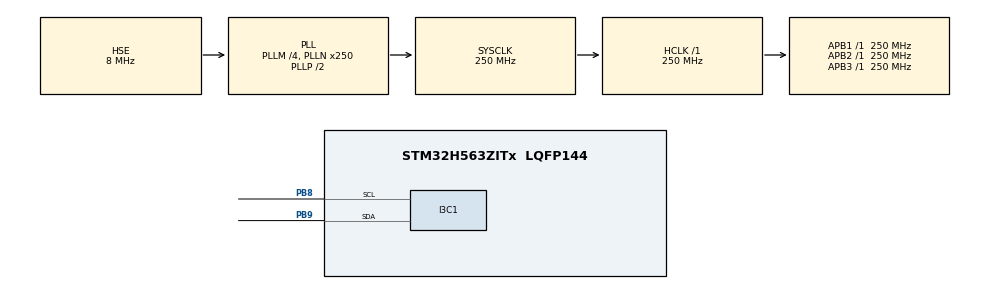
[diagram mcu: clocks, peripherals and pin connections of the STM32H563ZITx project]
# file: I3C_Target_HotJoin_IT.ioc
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CORTEX_M33_NS.userName=CORTEX_M33
I3C1.HotJoinRequest=ENABLE
I3C1.IBIPayloadSize=HAL_I3C_PAYLOAD_EMPTY
I3C1.Identifier=0xC6
I3C1.MIPIIdentifier=DEVICE_ID
I3C1.MaxReadDataSize=0xFF
I3C1.MaxWriteDataSize=0xFF
I3C1.RXFIFOThreshold=HAL_I3C_RXFIFO_THRESHOLD_1_4
I3C1.Register1=0x000000f8
I3C1.TXFIFOThreshold=HAL_I3C_TXFIFO_THRESHOLD_1_4
I3C1.hexBusAvailableDuration=0xf8
Mcu.Family=STM32H5
Mcu.Name=STM32H563ZITx
Mcu.Package=LQFP144
Mcu.UserConstants=DEVICE_ID,0x01
NVIC.I3C1_ER_IRQn=true\:0\:0\:false\:false\:true\:true\:true\:true
NVIC.I3C1_EV_IRQn=true\:0\:0\:false\:false\:true\:true\:true\:true
NVIC.PriorityGroup=NVIC_PRIORITYGROUP_4
PB8.Mode=Target
PB8.Signal=I3C1_SCL
PB9.Mode=Target
PB9.Signal=I3C1_SDA
PH0-OSC_IN(PH0).Mode=HSE-DIG-External-Clock-Source
PH0-OSC_IN(PH0).Signal=RCC_OSC_IN
ProjectManager.HeapSize=0x200
ProjectManager.StackSize=0x400
ProjectManager.TargetToolchain=EWARM V9.20
RCC.ADCFreq_Value=250000000
RCC.AHBFreq_Value=250000000
RCC.APB1Freq_Value=250000000
RCC.APB1TimFreq_Value=250000000
RCC.APB2Freq_Value=250000000
RCC.APB2TimFreq_Value=250000000
RCC.APB3Freq_Value=250000000
RCC.CSI_VALUE=4000000
RCC.CortexFreq_Value=250000000
RCC.EPOD_VALUE=8000000
RCC.HCLKFreq_Value=250000000
RCC.HSE_VALUE=8000000
RCC.HSI48_VALUE=48000000
RCC.HSIDiv=RCC_HSI_DIV1
RCC.HSI_VALUE=64000000
RCC.LSE_VALUE=32768
RCC.LSIRC_VALUE=32000
RCC.PLL1R=1
RCC.PLL2FRACN=0
RCC.PLLFRACN=0
RCC.PLLM=4
RCC.PLLN=250
RCC.PLLSourceVirtual=RCC_PLL1_SOURCE_HSE
RCC.PWR_Regulator_Voltage_Scale=PWR_REGULATOR_VOLTAGE_SCALE0
RCC.SYSCLKFreq_VALUE=250000000
RCC.SYSCLKSource=RCC_SYSCLKSOURCE_PLLCLK
RCC.USBFreq_Value=48000000
RCC.VCOOutputFreq_Value=500000000
VP_ICACHE_VS_ICACHE.Mode=DefaultMode
VP_PWR_VS_SECSignals.Mode=Security/Privilege
board=custom

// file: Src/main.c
/* USER CODE BEGIN Header */
/**
  ******************************************************************************
  * @file    I3C/I3C_Target_HotJoin_IT/Src/main.c
  * @author  MCD Application Team
  * @brief   This sample code shows how to use STM32H5xx I3C HAL API to
  *          launch a HotJoin procedure to a Controller with a communication
  *          process based on Interrupt transfer.
  ******************************************************************************
  * @attention
  *
  * Copyright (c) 2023 STMicroelectronics.
  * All rights reserved.
  *
  * This software is licensed under terms that can be found in the LICENSE file
  * in the root directory of this software component.
  * If no LICENSE file comes with this software, it is provided AS-IS.
  *
  ******************************************************************************
  */
/* USER CODE END Header */
#include "main.h"

I3C_HandleTypeDef hi3c1;

/* USER CODE BEGIN PV */
/*The returned dynamic address value after the hot join process.*/
__IO uint8_t ubDynamicAddress;
/* USER CODE END PV */

void SystemClock_Config(void);
static void MX_GPIO_Init(void);
static void MX_I3C1_Init(void);
static void MX_ICACHE_Init(void);

int main(void)
{

  /* MCU Configuration--------------------------------------------------------*/

  /* Reset of all peripherals, Initializes the Flash interface and the Systick. */
  HAL_Init();

  /* Configure the system clock */
  SystemClock_Config();

  /* Initialize all configured peripherals */
  MX_GPIO_Init();
  MX_I3C1_Init();
  MX_ICACHE_Init();
  /* USER CODE BEGIN 2 */
  /* Configure LED1 */
  BSP_LED_Init(LED1);

  /* Configure USER push-button */
  BSP_PB_Init(BUTTON_USER,BUTTON_MODE_GPIO);

  /* Wait for USER push-button press before starting the Communication */
  while (BSP_PB_GetState(BUTTON_USER) != GPIO_PIN_RESET)
  {
  }

  /* Wait for USER push-button release before starting the Communication */
  while (BSP_PB_GetState(BUTTON_USER) != GPIO_PIN_SET)
  {
  }

  /*##- Send HotJoin request ###############################################*/
  if(HAL_I3C_Tgt_HotJoinReq_IT(&hi3c1) != HAL_OK)
  {
    /* Error_Handler() function is called when error occurs. */
    Error_Handler();
  }

  /* USER CODE END 2 */

  /* Infinite loop */
  while (1)
  {

  }
}

void SystemClock_Config(void)
{
  RCC_OscInitTypeDef RCC_OscInitStruct = {0};
  RCC_ClkInitTypeDef RCC_ClkInitStruct = {0};

  /** Configure the main internal regulator output voltage
  */
  __HAL_PWR_VOLTAGESCALING_CONFIG(PWR_REGULATOR_VOLTAGE_SCALE0);

  while(!__HAL_PWR_GET_FLAG(PWR_FLAG_VOSRDY)) {}

  /** Initializes the RCC Oscillators according to the specified parameters
  * in the RCC_OscInitTypeDef structure.
  */
  RCC_OscInitStruct.OscillatorType = RCC_OSCILLATORTYPE_HSE;
  RCC_OscInitStruct.HSEState = RCC_HSE_BYPASS_DIGITAL;
  RCC_OscInitStruct.PLL.PLLState = RCC_PLL_ON;
  RCC_OscInitStruct.PLL.PLLSource = RCC_PLL1_SOURCE_HSE;
  RCC_OscInitStruct.PLL.PLLM = 4;
  RCC_OscInitStruct.PLL.PLLN = 250;
  RCC_OscInitStruct.PLL.PLLP = 2;
  RCC_OscInitStruct.PLL.PLLQ = 2;
  RCC_OscInitStruct.PLL.PLLR = 1;
  RCC_OscInitStruct.PLL.PLLRGE = RCC_PLL1_VCIRANGE_1;
  RCC_OscInitStruct.PLL.PLLVCOSEL = RCC_PLL1_VCORANGE_WIDE;
  RCC_OscInitStruct.PLL.PLLFRACN = 0;
  if (HAL_RCC_OscConfig(&RCC_OscInitStruct) != HAL_OK)
  {
    Error_Handler();
  }

  /** Initializes the CPU, AHB and APB buses clocks
  */
  RCC_ClkInitStruct.ClockType = RCC_CLOCKTYPE_HCLK|RCC_CLOCKTYPE_SYSCLK
                              |RCC_CLOCKTYPE_PCLK1|RCC_CLOCKTYPE_PCLK2
                              |RCC_CLOCKTYPE_PCLK3;
  RCC_ClkInitStruct.SYSCLKSource = RCC_SYSCLKSOURCE_PLLCLK;
  RCC_ClkInitStruct.AHBCLKDivider = RCC_SYSCLK_DIV1;
  RCC_ClkInitStruct.APB1CLKDivider = RCC_HCLK_DIV1;
  RCC_ClkInitStruct.APB2CLKDivider = RCC_HCLK_DIV1;
  RCC_ClkInitStruct.APB3CLKDivider = RCC_HCLK_DIV1;

  if (HAL_RCC_ClockConfig(&RCC_ClkInitStruct, FLASH_LATENCY_5) != HAL_OK)
  {
    Error_Handler();
  }

  /** Configure the programming delay
  */
  __HAL_FLASH_SET_PROGRAM_DELAY(FLASH_PROGRAMMING_DELAY_2);
}

static void MX_I3C1_Init(void)
{

  I3C_FifoConfTypeDef sFifoConfig = {0};
  I3C_TgtConfTypeDef sTgtConfig = {0};

  hi3c1.Instance = I3C1;
  hi3c1.Mode = HAL_I3C_MODE_TARGET;
  hi3c1.Init.TgtBusCharacteristic.BusAvailableDuration = 0xf8;
  if (HAL_I3C_Init(&hi3c1) != HAL_OK)
  {
    Error_Handler();
  }

  /** Configure FIFO
  */
  sFifoConfig.RxFifoThreshold = HAL_I3C_RXFIFO_THRESHOLD_1_4;
  sFifoConfig.TxFifoThreshold = HAL_I3C_TXFIFO_THRESHOLD_1_4;
  sFifoConfig.ControlFifo = HAL_I3C_CONTROLFIFO_DISABLE;
  sFifoConfig.StatusFifo = HAL_I3C_STATUSFIFO_DISABLE;

  if (HAL_I3C_SetConfigFifo(&hi3c1, &sFifoConfig) != HAL_OK)
  {
    Error_Handler();
  }

  /** Configure Target
  */
  sTgtConfig.Identifier = 0xC6;
  sTgtConfig.MIPIIdentifier = DEVICE_ID;
  sTgtConfig.CtrlRoleRequest = DISABLE;
  sTgtConfig.HotJoinRequest = ENABLE;
  sTgtConfig.IBIRequest = DISABLE;
  sTgtConfig.IBIPayload = DISABLE;
  sTgtConfig.IBIPayloadSize = HAL_I3C_PAYLOAD_EMPTY;
  sTgtConfig.MaxReadDataSize = 0xFF;
  sTgtConfig.MaxWriteDataSize = 0xFF;
  sTgtConfig.CtrlCapability = DISABLE;
  sTgtConfig.GroupAddrCapability = DISABLE;
  sTgtConfig.DataTurnAroundDuration = HAL_I3C_TURNAROUND_TIME_TSCO_LESS_12NS;
  sTgtConfig.MaxReadTurnAround = 0;
  sTgtConfig.MaxDataSpeed = HAL_I3C_GETMXDS_FORMAT_1;
  sTgtConfig.MaxSpeedLimitation = DISABLE;
  sTgtConfig.HandOffActivityState = HAL_I3C_HANDOFF_ACTIVITY_STATE_0;
  sTgtConfig.HandOffDelay = DISABLE;
  sTgtConfig.PendingReadMDB = DISABLE;
  if (HAL_I3C_Tgt_Config(&hi3c1, &sTgtConfig) != HAL_OK)
  {
    Error_Handler();
  }

}

static void MX_ICACHE_Init(void)
{

  /** Enable instruction cache (default 2-ways set associative cache)
  */
  if (HAL_ICACHE_Enable() != HAL_OK)
  {
    Error_Handler();
  }

}

static void MX_GPIO_Init(void)
{

  /* GPIO Ports Clock Enable */
  __HAL_RCC_GPIOH_CLK_ENABLE();
  __HAL_RCC_GPIOB_CLK_ENABLE();

}

/* USER CODE BEGIN 4 */
/**
  * @brief I3C Target Hot Join complete callback.
  *        The main objective of this user function is to check that a Hot Join process is finished
  * @par Called functions
  * - HAL_I3C_TgtHotJoinCallback()
  * @retval None
  */
void HAL_I3C_TgtHotJoinCallback(I3C_HandleTypeDef *hi3c, uint8_t dynamicAddress)
{
  /* Get received dynamic address */
  ubDynamicAddress = dynamicAddress;

  BSP_LED_Toggle(LED1);
}

/* USER CODE END 4 */

void Error_Handler(void)
{
  /* USER CODE BEGIN Error_Handler_Debug */
  /* Error if LED1 is slowly blinking (1 sec. period) */
  while (1)
  {
    BSP_LED_Toggle(LED1);
    HAL_Delay(1000);
  }
  /* USER CODE END Error_Handler_Debug */
}
